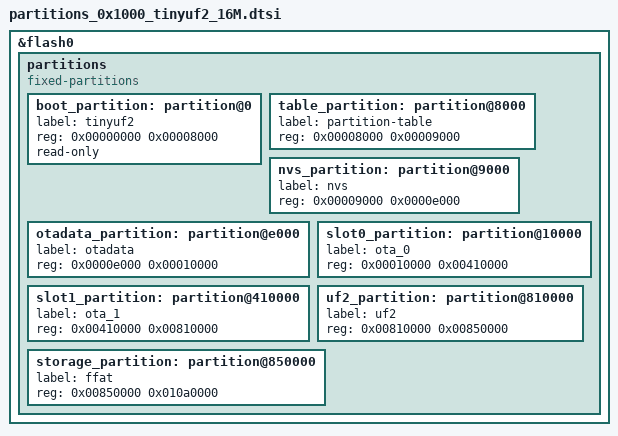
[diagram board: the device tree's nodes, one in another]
/*
 * SPDX-License-Identifier: Apache-2.0
 */

&flash0 {
    status = "okay";
    partitions {
        compatible = "fixed-partitions";
        #address-cells = <1>;
        #size-cells = <1>;

        /* Reserve 32kB for the bootloader */
        boot_partition: partition@0 {
            label = "tinyuf2";
            reg = <0x00000000 0x00008000>;
            read-only;
        };

        /* Reserve 4kB for the partition table */
        table_partition: partition@8000 {
            label = "partition-table";
            reg = <0x00008000 0x00009000>;
        };

        /* Reserve 20kB for non-volatile storage */
        nvs_partition: partition@9000 {
            label = "nvs";
            reg = <0x00009000 0x0000e000>;
        };

        /* Reserve 8kB for otadata partition */
        otadata_partition: partition@e000 {
            label = "otadata";
            reg = <0x0000e000 0x00010000>;
        };

        /* Reserve 2048kB for ota_0 partition */
        slot0_partition: partition@10000 {
            label = "ota_0";
            reg = <0x00010000 0x00410000>;
        };

        /* Reserve 2048kB for ota_1 partition */
        slot1_partition: partition@410000 {
            label = "ota_1";
            reg = <0x00410000 0x00810000>;
        };

        /* Reserve 256kB for uf2 partition */
        uf2_partition: partition@810000 {
            label = "uf2";
            reg = <0x00810000 0x00850000>;
        };

        /* Reserve 11968kB for storage partition (ffat) */
        storage_partition: partition@850000 {
            label = "ffat";
            reg = <0x00850000 0x010a0000>;
        };
    };
};
